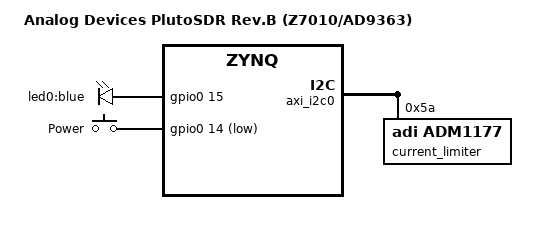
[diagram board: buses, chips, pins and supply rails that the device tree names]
/dts-v1/;
/include/ "zynq-pluto-sdr.dtsi"
#include <dt-bindings/input/input.h>
#include <dt-bindings/gpio/gpio.h>
#include <dt-bindings/interrupt-controller/irq.h>

&axi_i2c0 {
	current_limiter@5a {
		compatible = "adi,adm1177";
		reg = <0x5a>;
		adi,r-sense-mohm = <50>; /* 50 mOhm */
		adi,shutdown-threshold-ma = <1059>; /* 1.059 A */
		adi,vrange-high-enable;
	};
};

/ {
	model = "Analog Devices PlutoSDR Rev.B (Z7010/AD9363)";

	leds {
		compatible = "gpio-leds";
		led0 {
			label = "led0:blue";
			gpios = <&gpio0 15 0>;
			linux,default-trigger = "heartbeat";
		};
	};

	gpio_keys {
		compatible = "gpio-keys";
		#address-cells = <1>;
		#size-cells = <0>;
		autorepeat;

		power {
			interrupt-parent = <&gpio0>;
			//interrupts = <14 IRQ_TYPE_EDGE_FALLING>;

			label = "Power";
			gpios = <&gpio0 14 GPIO_ACTIVE_LOW>;
			linux,code = <KEY_POWER>;
			gpio-key,wakeup;
		};

	};
};
